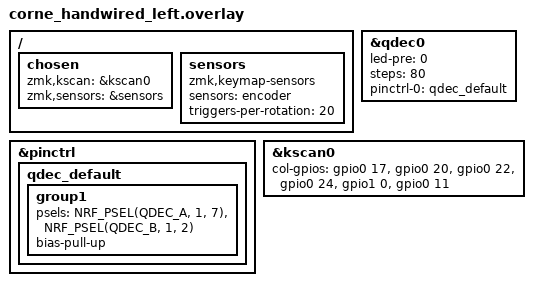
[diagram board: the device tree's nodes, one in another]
/*
 * Left Half - Corne Handwired
 * Using nRF52840 hardware QDEC driver for encoder
 * Encoder: A=P1.07, B=P1.02
 */

#include "corne_handwired.dtsi"

/ {
    chosen {
        zmk,kscan = &kscan0;
        zmk,sensors = &sensors;
    };

    sensors: sensors {
        compatible = "zmk,keymap-sensors";
        sensors = <&encoder>;
        triggers-per-rotation = <20>;
    };
};

&pinctrl {
    qdec_default: qdec_default {
        group1 {
            psels = <NRF_PSEL(QDEC_A, 1, 7)>,
                    <NRF_PSEL(QDEC_B, 1, 2)>;
            bias-pull-up;
        };
    };
};

encoder: &qdec0 {
    status = "okay";
    led-pre = <0>;
    steps = <80>;
    pinctrl-0 = <&qdec_default>;
    pinctrl-names = "default";
};

&kscan0 {
    col-gpios
        = <&gpio0 17 GPIO_ACTIVE_HIGH>
        , <&gpio0 20 GPIO_ACTIVE_HIGH>
        , <&gpio0 22 GPIO_ACTIVE_HIGH>
        , <&gpio0 24 GPIO_ACTIVE_HIGH>
        , <&gpio1 0  GPIO_ACTIVE_HIGH>
        , <&gpio0 11 GPIO_ACTIVE_HIGH>
        ;
};
